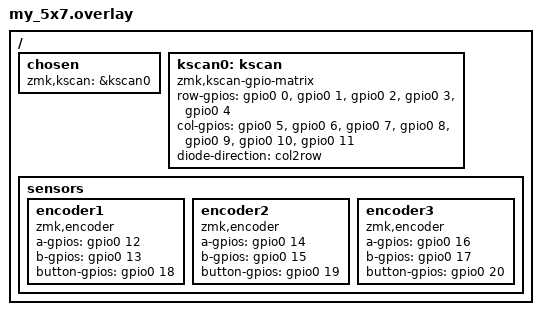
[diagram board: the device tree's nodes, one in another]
/ {
    chosen {
        zmk,kscan = &kscan0;
    };

    kscan0: kscan {
        compatible = "zmk,kscan-gpio-matrix";
        row-gpios = <&gpio0 0 GPIO_ACTIVE_HIGH>,
                    <&gpio0 1 GPIO_ACTIVE_HIGH>,
                    <&gpio0 2 GPIO_ACTIVE_HIGH>,
                    <&gpio0 3 GPIO_ACTIVE_HIGH>,
                    <&gpio0 4 GPIO_ACTIVE_HIGH>;
        col-gpios = <&gpio0 5 GPIO_ACTIVE_HIGH>,
                    <&gpio0 6 GPIO_ACTIVE_HIGH>,
                    <&gpio0 7 GPIO_ACTIVE_HIGH>,
                    <&gpio0 8 GPIO_ACTIVE_HIGH>,
                    <&gpio0 9 GPIO_ACTIVE_HIGH>,
                    <&gpio0 10 GPIO_ACTIVE_HIGH>,
                    <&gpio0 11 GPIO_ACTIVE_HIGH>;
        diode-direction = "col2row";
    };

    sensors {
        encoder1: encoder1 {
            compatible = "zmk,encoder";
            a-gpios = <&gpio0 12 GPIO_ACTIVE_HIGH>;
            b-gpios = <&gpio0 13 GPIO_ACTIVE_HIGH>;
            button-gpios = <&gpio0 18 GPIO_ACTIVE_HIGH>;   // ปุ่มกดของ encoder1
        };
        encoder2: encoder2 {
            compatible = "zmk,encoder";
            a-gpios = <&gpio0 14 GPIO_ACTIVE_HIGH>;
            b-gpios = <&gpio0 15 GPIO_ACTIVE_HIGH>;
            button-gpios = <&gpio0 19 GPIO_ACTIVE_HIGH>;   // ปุ่มกดของ encoder2
        };
        encoder3: encoder3 {
            compatible = "zmk,encoder";
            a-gpios = <&gpio0 16 GPIO_ACTIVE_HIGH>;
            b-gpios = <&gpio0 17 GPIO_ACTIVE_HIGH>;
            button-gpios = <&gpio0 20 GPIO_ACTIVE_HIGH>;   // ปุ่มกดของ encoder3
        };
    };
};
